# SERDES_10G0 register map
Vendor: Texas Instruments
Registers are 32-bit, access per field, reset 0x0 unless marked. A register's access mark holds for its fields unless they carry their own. Offsets are as the file gives them; [hi:lo] are bit positions; {n}, {i} and the like mark numbered series.

## SERDES_10G0 (part 4 of 8)
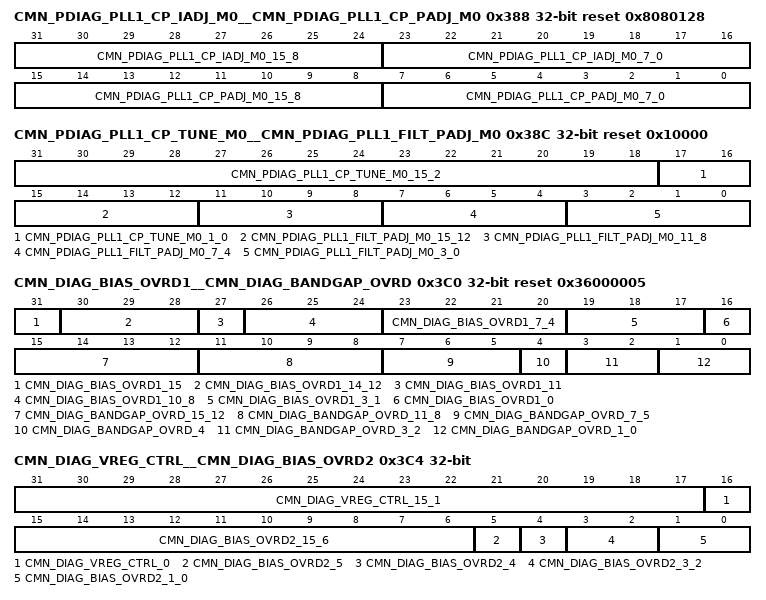
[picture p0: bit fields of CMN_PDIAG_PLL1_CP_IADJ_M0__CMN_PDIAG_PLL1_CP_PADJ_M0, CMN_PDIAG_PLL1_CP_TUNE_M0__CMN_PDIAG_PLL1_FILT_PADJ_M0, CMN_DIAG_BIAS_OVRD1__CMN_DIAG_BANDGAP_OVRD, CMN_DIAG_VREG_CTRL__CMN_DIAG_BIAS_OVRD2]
0x388 CMN_PDIAG_PLL1_CP_IADJ_M0__CMN_PDIAG_PLL1_CP_PADJ_M0 rw reset 0x8080128 — PLL 1 charge pump proportional path adjust register mode 0
  [31:24] CMN_PDIAG_PLL1_CP_IADJ_M0_15_8 — PLL charge pump integral path capacitance adjust: Adjusts the charge pump integral path capacitance, by driving the cmnda_pll1_cp_int_cap_adj signal going to the analog.
  [23:16] CMN_PDIAG_PLL1_CP_IADJ_M0_7_0 — PLL charge pump integral path current adjust: Adjusts the charge pump integral path current, by driving the cmnda_pll1_cp_int_cur_adj signal going to the analog.
  [15:8] CMN_PDIAG_PLL1_CP_PADJ_M0_15_8 — PLL charge pump proportional path capacitance adjust: Adjusts the charge pump proportional path capacitance, by driving the cmnda_pll1_cp_prop_cap_adj signal going to the analog.
  [7:0] CMN_PDIAG_PLL1_CP_PADJ_M0_7_0 — PLL charge pump proportional path current adjust: Adjusts the charge pump proportional path current, by driving the cmnda_pll1_cp_prop_cur_adj signal going to the analog.
0x38C CMN_PDIAG_PLL1_CP_TUNE_M0__CMN_PDIAG_PLL1_FILT_PADJ_M0 reset 0x10000 — PLL 1 proportional path filter adjust register mode 0
  [31:18] CMN_PDIAG_PLL1_CP_TUNE_M0_15_2 ro — Reserved
  [17:16] CMN_PDIAG_PLL1_CP_TUNE_M0_1_0 rw — PLL charge pump calibration reference voltage tune: Adjusts the charge pump calibration reference voltage, by driving the cmnda_pll1_cp_vref_tune signal going to the analog.
  [15:12] CMN_PDIAG_PLL1_FILT_PADJ_M0_15_12 ro — Reserved
  [11:8] CMN_PDIAG_PLL1_FILT_PADJ_M0_11_8 rw — PLL proportional path filter capacitance adjust: Adjusts the proportional path filter capacitance, by driving the cmnda_pll1_filt_c_adj signal going to the analog.
  [7:4] CMN_PDIAG_PLL1_FILT_PADJ_M0_7_4 ro — Reserved
  [3:0] CMN_PDIAG_PLL1_FILT_PADJ_M0_3_0 rw — PLL proportional path filter resistance adjust: Adjusts the proportional path filter resistance, by driving the cmnda_pll1_filt_r_adj signal going to the analog.
0x3C0 CMN_DIAG_BIAS_OVRD1__CMN_DIAG_BANDGAP_OVRD reset 0x36000005 — Bandgap override register
  [31] CMN_DIAG_BIAS_OVRD1_15 ro — Reserved
  [30:28] CMN_DIAG_BIAS_OVRD1_14_12 rw — Receiver resistor calibration current adjust: This field is used to adjust the receiver resistor calibration bias current.
  [27] CMN_DIAG_BIAS_OVRD1_11 ro — Reserved
  [26:24] CMN_DIAG_BIAS_OVRD1_10_8 rw — Transmitter resistor calibration current adjust: This field is used to adjust the transmitter resistor calibration bias current.
  [23:20] CMN_DIAG_BIAS_OVRD1_7_4 rw — Reserved - spare
  [19:17] CMN_DIAG_BIAS_OVRD1_3_1 ro — Reserved
  [16] CMN_DIAG_BIAS_OVRD1_0 rw — Reserved - spare
  [15:12] CMN_DIAG_BANDGAP_OVRD_15_12 ro — Reserved
  [11:8] CMN_DIAG_BANDGAP_OVRD_11_8 ro — Bandgap startup circuit startup count : Identifies the status of the bandgap startup counter.
  [7:5] CMN_DIAG_BANDGAP_OVRD_7_5 ro — Reserved
  [4] CMN_DIAG_BANDGAP_OVRD_4 rw — Bandgap startup circuit select : Selects the startup circuit to be used for the bias / bandgap circuits, by driving the cmnda_bias_bg_start_sel signal going to the analog.
  [3:2] CMN_DIAG_BANDGAP_OVRD_3_2 rw — Bandgap startup circuit sense voltage adjust : This field is used to adjust the bandgap startup circuit sense voltage, by driving the cmnda_bias_bg_start_adj signal to the analog.
  [1:0] CMN_DIAG_BANDGAP_OVRD_1_0 rw — Bandgap voltage adjust : This field is used to adjust the bandgap voltage, by driving the cmnda_bias_bg_adj signal to the analog.
0x3C4 CMN_DIAG_VREG_CTRL__CMN_DIAG_BIAS_OVRD2 — Bias override register 2
  [31:17] CMN_DIAG_VREG_CTRL_15_1 ro — Reserved
  [16] CMN_DIAG_VREG_CTRL_0 rw — Voltage regulator reference voltage select: Selects the reference voltage used for the voltage regulator in common, by driving the cmnda_vreg_ref_sel signal to the analog.
  [15:6] CMN_DIAG_BIAS_OVRD2_15_6 ro — Reserved
  [5] CMN_DIAG_BIAS_OVRD2_5 rw — Bias filter bypass enable override enable: When active (1'b1), the bias filter bypass enable override bit in this register, can be used to directly control the bias filter bypass enable function.
  [4] CMN_DIAG_BIAS_OVRD2_4 rw — Bias filter bypass enable override: When enabled by the bias filter bypass enable override enable bit in this register, this bit will directly control the bias filter bypass enable function.
  [3:2] CMN_DIAG_BIAS_OVRD2_3_2 ro — Reserved
  [1:0] CMN_DIAG_BIAS_OVRD2_1_0 rw — Regulator bandgap reference voltage adjust: This field is used to adjust the regulator bandgap reference voltage, by driving the cmnda_bias_vreg_adj signal to the analog.
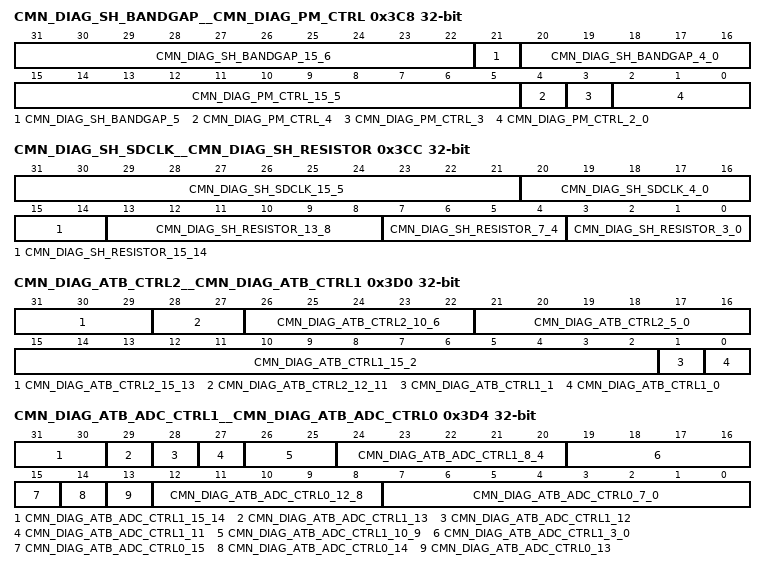
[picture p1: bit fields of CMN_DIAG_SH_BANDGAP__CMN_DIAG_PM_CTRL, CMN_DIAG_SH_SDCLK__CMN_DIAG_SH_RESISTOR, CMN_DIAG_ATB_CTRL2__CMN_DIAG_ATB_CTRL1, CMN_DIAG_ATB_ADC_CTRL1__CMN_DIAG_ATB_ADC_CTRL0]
0x3C8 CMN_DIAG_SH_BANDGAP__CMN_DIAG_PM_CTRL — Common process monitor control register
  [31:22] CMN_DIAG_SH_BANDGAP_15_6 ro — Reserved
  [21] CMN_DIAG_SH_BANDGAP_5 ro — Bandgap up value: Bandgap calibration up signal value, as it is currently captured in the sample and hold latches.
  [20:16] CMN_DIAG_SH_BANDGAP_4_0 ro — Bandgap auto zero select value: Bandgap calibration auto zero select signal value, as it is currently captured in the sample and hold latches.
  [15:5] CMN_DIAG_PM_CTRL_15_5 ro — Reserved
  [4] CMN_DIAG_PM_CTRL_4 rw — Process monitor enable: Enables the analog process monitor, by driving the cmnda_pcm_en signal to the analog.
  [3] CMN_DIAG_PM_CTRL_3 ro — Reserved
  [2:0] CMN_DIAG_PM_CTRL_2_0 rw — Process monitor mode select: Selects the mode of the analog process monitor, by driving the cmnda_pcm_sel signal to the analog.
0x3CC CMN_DIAG_SH_SDCLK__CMN_DIAG_SH_RESISTOR ro — Sample and hold resistor calibration code register
  [31:21] CMN_DIAG_SH_SDCLK_15_5 — Reserved
  [20:16] CMN_DIAG_SH_SDCLK_4_0 — Signal detect clock code: Signal detect clock calibration code signal value, as it is currently captured in the sample and hold latches.
  [15:14] CMN_DIAG_SH_RESISTOR_15_14 — Reserved
  [13:8] CMN_DIAG_SH_RESISTOR_13_8 — TX resistor code: TX resistor calibration code signal value, as it is currently captured in the sample and hold latches.
  [7:4] CMN_DIAG_SH_RESISTOR_7_4 — Reserved
  [3:0] CMN_DIAG_SH_RESISTOR_3_0 — RX resistor code: RX resistor calibration code signal value, as it is currently captured in the sample and hold latches.
0x3D0 CMN_DIAG_ATB_CTRL2__CMN_DIAG_ATB_CTRL1 — ATB control register 1
  [31:29] CMN_DIAG_ATB_CTRL2_15_13 ro — Reserved
  [28:27] CMN_DIAG_ATB_CTRL2_12_11 rw — ATB component type select: These bits specify which component type is currently selected by the ATB, as specified below.
  [26:22] CMN_DIAG_ATB_CTRL2_10_6 rw — ATB component sub address: Specifies the sub address of the component being selected.
  [21:16] CMN_DIAG_ATB_CTRL2_5_0 rw — ATB test point address: Specifies the exact point in the selected analog component to be observed.
  [15:2] CMN_DIAG_ATB_CTRL1_15_2 ro — Reserved
  [1] CMN_DIAG_ATB_CTRL1_1 rw — Core side ATB enable: When active (1'b) and the ATB enable bit in this register is also active, the ATB signals will be driven on the core side ATB signals.
  [0] CMN_DIAG_ATB_CTRL1_0 rw — ATB enable: When active (1'b1), the ATB test function is enabled.
0x3D4 CMN_DIAG_ATB_ADC_CTRL1__CMN_DIAG_ATB_ADC_CTRL0 — ATB ADC control register 0
  [31:30] CMN_DIAG_ATB_ADC_CTRL1_15_14 ro — Reserved
  [29] CMN_DIAG_ATB_ADC_CTRL1_13 rw — ATB ADC offset correction enable : Enables internal auto generated offset correction mode, by driving the cmnda_atba2d_en_off_cor signal to the analog.
  [28] CMN_DIAG_ATB_ADC_CTRL1_12 rw — ATB ADC force cap values : Forces a positive or negative voltage on the internal cap, by driving the cmnda_atba2d_frc_val signal to the analog.
  [27] CMN_DIAG_ATB_ADC_CTRL1_11 rw — ATB ADC enable manual offset correction : When this signal is active, the value in the ATB ADC manual offset correction value field of this register is used to manually control the offset correction, by driving the cmnda_atba2d_off_byp_en signal to the analog.
  [26:25] CMN_DIAG_ATB_ADC_CTRL1_10_9 ro — Reserved
  [24:20] CMN_DIAG_ATB_ADC_CTRL1_8_4 rw — ATB ADC manual offset correction value : When the ATB ADC enable manual offset correction bit in this register is active, this field is used to manually control the offset correction, by driving the cmnda_atba2d_off_adj_byp signal to the analog.
  [19:16] CMN_DIAG_ATB_ADC_CTRL1_3_0 rw — ATB ADC mode : This field indicates the mode the analog to digital converter is in.
  [15] CMN_DIAG_ATB_ADC_CTRL0_15 rw — ATB analog ADC enable: This enables the analog ADC function, by driving the cmnda_atba2d_en signal to the analog.
  [14] CMN_DIAG_ATB_ADC_CTRL0_14 rw — Start ATB ADC process: Activating (1'b1) this bit will start the ATB ADC process.
  [13] CMN_DIAG_ATB_ADC_CTRL0_13 ro — ATB ADC process done: This bit will be set to 1'b1 when the ATB ADC process is complete, and the data in the ATB ADC code field of this register is considered valid.
  [12:8] CMN_DIAG_ATB_ADC_CTRL0_12_8 ro — Reserved
  [7:0] CMN_DIAG_ATB_ADC_CTRL0_7_0 ro — ATB ADC data code: This is the digital code representing the level of the analog ATB signal that was digitized by the analog ADC.
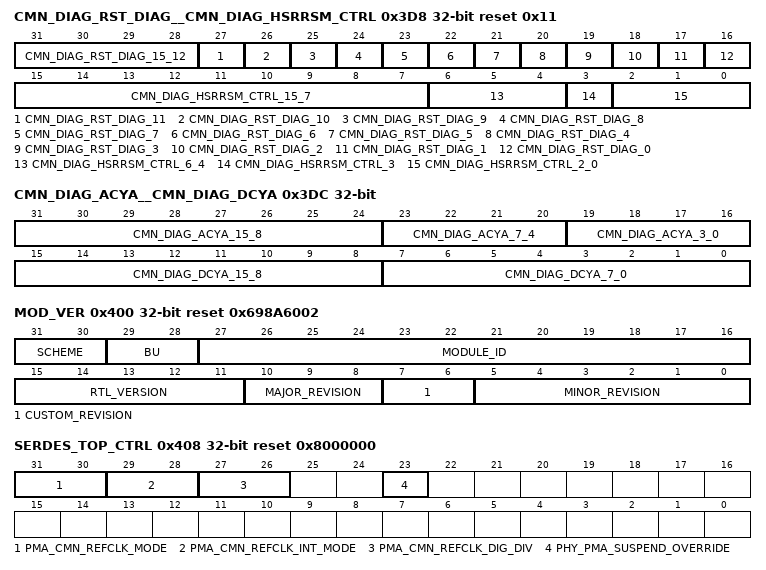
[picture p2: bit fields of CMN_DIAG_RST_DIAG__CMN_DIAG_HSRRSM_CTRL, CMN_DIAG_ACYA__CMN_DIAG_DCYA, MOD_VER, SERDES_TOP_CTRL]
0x3D8 CMN_DIAG_RST_DIAG__CMN_DIAG_HSRRSM_CTRL reset 0x11 — Common high speed reset release state machine control register
  [31:28] CMN_DIAG_RST_DIAG_15_12 ro — Reserved
  [27] CMN_DIAG_RST_DIAG_11 ro — Current state of the cmn_sd_clk_cal_fb_clk_reset_n reset.
  [26] CMN_DIAG_RST_DIAG_10 ro — Current state of the cmn_sd_clk_cal_ref_clk_reset_n reset.
  [25] CMN_DIAG_RST_DIAG_9 ro — Current state of the cmn_pll1_dsm_reset_n reset.
  [24] CMN_DIAG_RST_DIAG_8 ro — Current state of the cmn_pll0_dsm_reset_n reset.
  [23] CMN_DIAG_RST_DIAG_7 ro — Current state of the cmn_pll1_vco_cal_fbdiv_clk_reset_n reset.
  [22] CMN_DIAG_RST_DIAG_6 ro — Current state of the cmn_pll1_lock_det_fbdiv_clk_reset_n reset.
  [21] CMN_DIAG_RST_DIAG_5 ro — Current state of the cmn_pll1_vco_cal_ref_clk_reset_n reset.
  [20] CMN_DIAG_RST_DIAG_4 ro — Current state of the cmn_pll1_lock_det_ref_clk_reset_n reset.
  [19] CMN_DIAG_RST_DIAG_3 ro — Current state of the cmn_pll0_vco_cal_fbdiv_clk_reset_n reset.
  [18] CMN_DIAG_RST_DIAG_2 ro — Current state of the cmn_pll0_lock_det_fbdiv_clk_reset_n reset.
  [17] CMN_DIAG_RST_DIAG_1 ro — Current state of the cmn_pll0_vco_cal_ref_clk_reset_n reset.
  [16] CMN_DIAG_RST_DIAG_0 ro — Current state of the cmn_pll0_lock_det_ref_clk_reset_n reset.
  [15:7] CMN_DIAG_HSRRSM_CTRL_15_7 ro — Reserved
  [6:4] CMN_DIAG_HSRRSM_CTRL_6_4 rw — Transceiver reset delay : Species the number of PSM clock cycles the transceiver common high speed reset state machine stays in the delay state.
  [3] CMN_DIAG_HSRRSM_CTRL_3 ro — Reserved
  [2:0] CMN_DIAG_HSRRSM_CTRL_2_0 rw — Transmitter reset delay : Species the number of PSM clock cycles the transmitter common high speed reset state machine stays in the delay state.
0x3DC CMN_DIAG_ACYA__CMN_DIAG_DCYA — Common digital functions cover your alternatives register
  [31:24] CMN_DIAG_ACYA_15_8 ro — Reserved
  [23:20] CMN_DIAG_ACYA_7_4 rw — Reserved - spare
  [19:16] CMN_DIAG_ACYA_3_0 rw — PLL charge pump proportional gain adjust: Adjusts the charge pump gain for the PLLs to help manage bandwidth.
  [15:8] CMN_DIAG_DCYA_15_8 ro — Reserved
  [7:0] CMN_DIAG_DCYA_7_0 rw — Reserved - spare
0x400 MOD_VER ro reset 0x698A6002 — The Module and Version Register identifies the module identifier and revision of the WIZmodule.
  [31:30] SCHEME — Module Scheme
  [29:28] BU — Module BU
  [27:16] MODULE_ID
  [15:11] RTL_VERSION
  [10:8] MAJOR_REVISION
  [7:6] CUSTOM_REVISION
  [5:0] MINOR_REVISION
0x404 SERDES_CTRL rw — Sets the SERDES control state.
  [31] POR_EN — The POR_EN allows the system to place the SERDES in a reset state, Access to the SERDES registers are ignored.
0x408 SERDES_TOP_CTRL rw reset 0x8000000 — The SERDES Top Level Control
  [31:30] PMA_CMN_REFCLK_MODE — The PMA common differential reference clock mode - Sets the mode of operation for differential reference clock input.
  [29:28] PMA_CMN_REFCLK_INT_MODE — The PMA common internal reference clock mode - Sets the mode of operation for internal reference clock input.
  [27:26] PMA_CMN_REFCLK_DIG_DIV — The PMA common reference clock digital divide ratio select - Must be set before the de-assertion of apb_preset_n/phy_reset_n.
  [23] PHY_PMA_SUSPEND_OVERRIDE — The PHY PMA common suspend override enable:
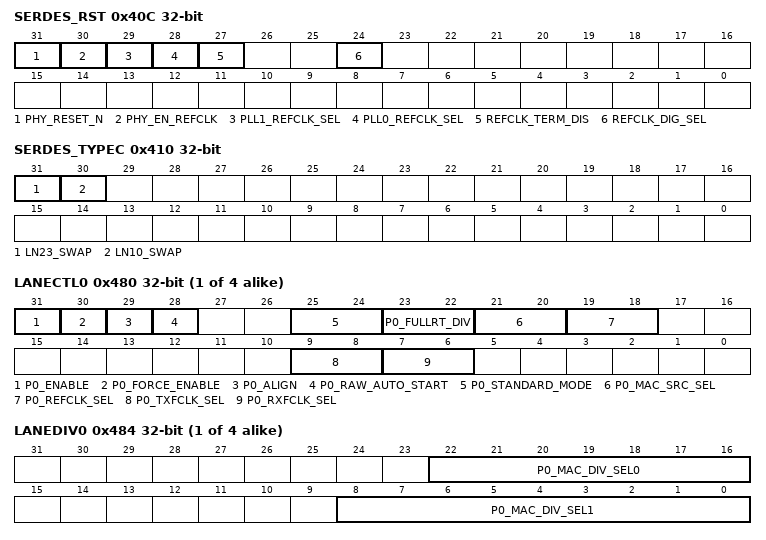
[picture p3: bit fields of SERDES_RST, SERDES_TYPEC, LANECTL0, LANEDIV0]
0x40C SERDES_RST rw — The SERDES Reset Register controls the Phy reset and REFCLK selection for the SERDES.
  [31] PHY_RESET_N — The PHY reset : Asserting this signal low will reset all PHY logic for the entire PHY with the exception of the APB registers and TAP controller.
  [30] PHY_EN_REFCLK — The PHY reference clock enable: When cmn_refclk_&lt;p/m&gt; is configured as a reference clock output,
  [29] PLL1_REFCLK_SEL — The PMA common PLL1 reference clock source select -
  [28] PLL0_REFCLK_SEL — The PMA common PLL0 reference clock source select -
  [27] REFCLK_TERM_DIS — The PMA common differential reference clock termination disable - enables/disables termination for difference reference clock input (cmn_refclk_&lt;p/m&gt;).
  [24] REFCLK_DIG_SEL — The PMA common reference clock select - Selects the reference clock source for the digital logic between cmn_refclk_&lt;p/m&gt; and pma_cmn_refclk_int.
0x410 SERDES_TYPEC rw — The SERDES Type C control register allows the external lanes selection to be swapped.
  [31] LN23_SWAP — The~iln23_swap will swap the lanes 2 and 3.
  [30] LN10_SWAP — The ~iln10_swap will swap the lanes 0 and 1.
{0x480+0x40*i} LANECTL{i} rw (i=0..3) — The Lane Control Register sets the lane specific modes of operation.
  [31] P{i}_ENABLE — The p{i}_enable is AND'd with the IPx_LNy_reset_n to enable the lane.
  [30] P{i}_FORCE_ENABLE — The p{i}_force_enable is OR'd with the IPx_LNy_reset_n to force enable the lane.
  [29] P{i}_ALIGN — The p{i}_align will auto align the RAW interface to 8B10B comma characters.
  [28] P{i}_RAW_AUTO_START — The p{i}_raw_auto_start will auto sequence the RAW interface according to the configuration settings
  [25:24] P{i}_STANDARD_MODE — Standard Mode
  [23:22] P{i}_FULLRT_DIV — Full Rate divider for 2x MAC speed mode.
  [21:20] P{i}_MAC_SRC_SEL — MAC clock source select : Selects which PMA clock to use as clock souse for pcs_mac_clk*_ln_*.
  [19:18] P{i}_REFCLK_SEL — Refclk Select determines which clocks will be used for the IP refclk signal.
  [9:8] P{i}_TXFCLK_SEL — Fclk Select determines which clocks will be used for the IP txfclk signal.
  [7:6] P{i}_RXFCLK_SEL — Fclk Select determines which clocks will be used for the IP rxfclk signal.
{0x484+0x40*i} LANEDIV{i} rw (i=0..3) — The Lane Divider Register sets the lane specific dividers of
  [22:16] P{i}_MAC_DIV_SEL0 — The reg_p{i}_mac_div_sel0 controls the divider for lane {i} MAC clock divider ratio select : Selects the divider ratio for pcs_mac_clk_divx0_ln_*.
  [8:0] P{i}_MAC_DIV_SEL1 — The reg_p{i}_mac_div_sel1 controls the divider for lane {i} MAC clock divider ratio select : Selects the divider ratio for pcs_mac_clk_divx1_ln_*.
{0x488+0x40*i} LANALIGN{i} ro (i=0..3) — The Lane Align reports the 8B10B alignment delay from the Comma aligner when 8B10B protocol is used in RAW mode.
  [5:0] P{i}_ALIGN_RX_DELAY — The reg_p{i}_align_rx_delay indicates the number of bits that are added to align the data to an 8B10B alignment.
{0x48C+0x40*i} LANESTS{i} ro (i=0..3) — The lane Status reports the lane state information for debug purposes.
  [1] P{i}_MASTER — The reg_p{i}_master indicates the lane is a base lane for a multi lane link.
0x5F8 DTB_MUX_SEL rw — The digital test bus mux select determines the value on the test bus.
  [4:0] DTB_MUX_SEL
0x5FC DIAG_TEST rw — The Diagnostic Test Register allows the system to validate the read and write of all data bits.
  [31:0] DIAG_REG — Diagnostic register.
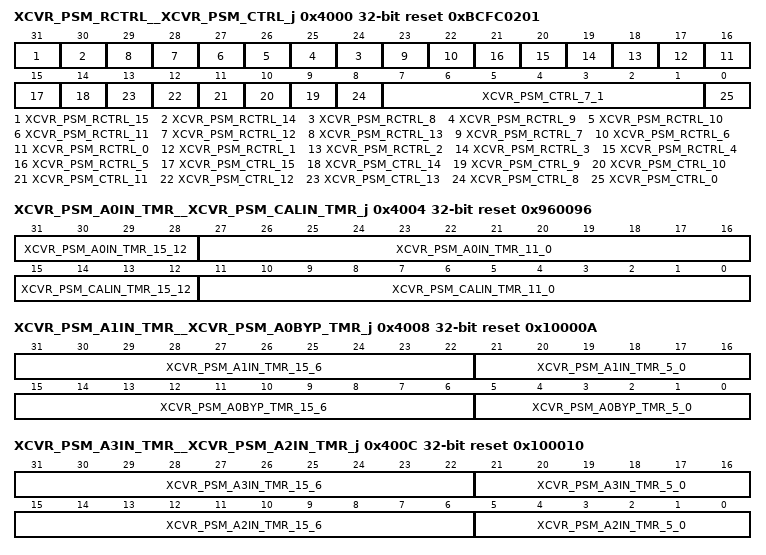
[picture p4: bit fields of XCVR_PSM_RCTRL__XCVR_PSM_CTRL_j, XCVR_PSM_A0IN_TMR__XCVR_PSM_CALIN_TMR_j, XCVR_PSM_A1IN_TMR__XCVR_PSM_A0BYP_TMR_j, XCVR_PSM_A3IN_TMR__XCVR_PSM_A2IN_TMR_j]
0x4000 XCVR_PSM_RCTRL__XCVR_PSM_CTRL_j reset 0xBCFC0201 — Power state machine control register Offset = 4000h + (j * 400h); where j = 0h to 3h
  [31] XCVR_PSM_RCTRL_15 rw — RX reset active ready : Controls the state the receiver reset is changed to when in the ready power state.
  [30] XCVR_PSM_RCTRL_14 rw — RX reset active calibration : Controls the state the receiver reset is changed to when in the calibration power state.
  [n+16] XCVR_PSM_RCTRL_{n} rw (n=8..13) — RX reset active A{n-8} : Controls the state the receiver reset is changed to when in the A{n-8} entry power state.
  [23] XCVR_PSM_RCTRL_7 rw — TX reset active ready : Controls the state the transmitter reset is changed to when in the ready power state.
  [22] XCVR_PSM_RCTRL_6 rw — TX reset active calibration : Controls the state the transmitter reset is changed to when in the calibration power state.
  [n+16] XCVR_PSM_RCTRL_{n} rw (n=0..5) — TX reset active A{n} : Controls the state the transmitter reset is changed to when in the A{n} entry power state.
  [15] XCVR_PSM_CTRL_15 ro — Reserved
  [14] XCVR_PSM_CTRL_14 rw — Bypass A0 in delay from PSM ready : When this bit is active (1'b1), the A0 input delay is bypassed when transitioning from the PSM ready state to the A0 power state.
  [n] XCVR_PSM_CTRL_{n} rw (n=9..13) — Bypass A0 in delay from A{n-8} : When this bit is active (1'b1), the A0 input delay is bypassed when transitioning from the A{n-8} to the A0 power state.
  [8] XCVR_PSM_CTRL_8 ro — Reserved
  [7:1] XCVR_PSM_CTRL_7_1 ro — Reserved
  [0] XCVR_PSM_CTRL_0 rw — Reserved - spare (must remain set to 1'b1).
0x4004 XCVR_PSM_A0IN_TMR__XCVR_PSM_CALIN_TMR_j reset 0x960096 — PSM calibration in delay timer register Offset = 4004h + (j * 400h); where j = 0h to 3h
  [31:28] XCVR_PSM_A0IN_TMR_15_12 ro — Reserved
  [27:16] XCVR_PSM_A0IN_TMR_11_0 rw — A0 in delay state timer value : Value used for the timer when the power state machine is in the A0 in delay state, unless the timer is bypassed under the control of the bypass A0 bits in the Power state machine control register.
  [15:12] XCVR_PSM_CALIN_TMR_15_12 ro — Reserved
  [11:0] XCVR_PSM_CALIN_TMR_11_0 rw — PSM calibration in delay state timer value : Value used for the timer when the power state machine is in the PSM calibration in delay state.
0x4008 XCVR_PSM_A1IN_TMR__XCVR_PSM_A0BYP_TMR_j reset 0x10000A — A0 in bypass timer register Offset = 4008h + (j * 400h); where j = 0h to 3h
  [31:22] XCVR_PSM_A1IN_TMR_15_6 ro — Reserved
  [21:16] XCVR_PSM_A1IN_TMR_5_0 rw — A1 in delay state timer value : Value used for the timer when the power state machine is in the A1 in delay state.
  [15:6] XCVR_PSM_A0BYP_TMR_15_6 ro — Reserved
  [5:0] XCVR_PSM_A0BYP_TMR_5_0 rw — A0 in delay state bypass timer value : Value used for the timer when the power state machine is in the A0 in delay state and the timer is bypassed under the control of the bypass A0 bits in the Power state machine control register.
0x400C XCVR_PSM_A3IN_TMR__XCVR_PSM_A2IN_TMR_j reset 0x100010 — A2 in delay timer register Offset = 400Ch + (j * 400h); where j = 0h to 3h
  [31:22] XCVR_PSM_A3IN_TMR_15_6 ro — Reserved
  [21:16] XCVR_PSM_A3IN_TMR_5_0 rw — A3 in delay state timer value : Value used for the timer when the power state machine is in the A3 in delay state.
  [15:6] XCVR_PSM_A2IN_TMR_15_6 ro — Reserved
  [5:0] XCVR_PSM_A2IN_TMR_5_0 rw — A2 in delay state timer value : Value used for the timer when the power state machine is in the A2 in delay state.
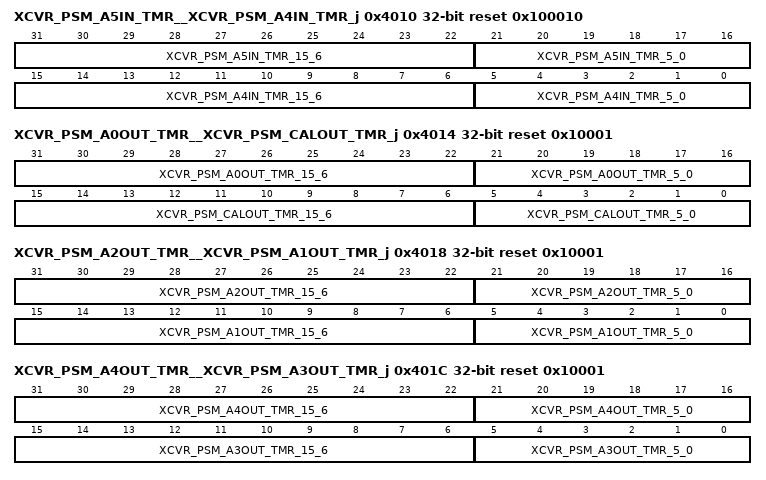
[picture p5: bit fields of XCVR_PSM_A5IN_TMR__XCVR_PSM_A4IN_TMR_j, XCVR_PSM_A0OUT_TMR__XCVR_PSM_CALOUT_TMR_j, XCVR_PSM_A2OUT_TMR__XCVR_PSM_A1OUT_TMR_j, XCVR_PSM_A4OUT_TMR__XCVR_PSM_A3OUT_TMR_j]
0x4010 XCVR_PSM_A5IN_TMR__XCVR_PSM_A4IN_TMR_j reset 0x100010 — A4 in delay timer register Offset = 4010h + (j * 400h); where j = 0h to 3h
  [31:22] XCVR_PSM_A5IN_TMR_15_6 ro — Reserved
  [21:16] XCVR_PSM_A5IN_TMR_5_0 rw — A5 in delay state timer value : Value used for the timer when the power state machine is in the A5 in delay state.
  [15:6] XCVR_PSM_A4IN_TMR_15_6 ro — Reserved
  [5:0] XCVR_PSM_A4IN_TMR_5_0 rw — A4 in delay state timer value : Value used for the timer when the power state machine is in the A4 in delay state.
0x4014 XCVR_PSM_A0OUT_TMR__XCVR_PSM_CALOUT_TMR_j reset 0x10001 — PSM calibration out delay timer register Offset = 4014h + (j * 400h); where j = 0h to 3h
  [31:22] XCVR_PSM_A0OUT_TMR_15_6 ro — Reserved
  [21:16] XCVR_PSM_A0OUT_TMR_5_0 rw — A0 out delay state timer value : Value used for the timer when the power state machine is in the A0 out delay state.
  [15:6] XCVR_PSM_CALOUT_TMR_15_6 ro — Reserved
  [5:0] XCVR_PSM_CALOUT_TMR_5_0 rw — PSM calibration out delay state timer value : Value used for the timer when the power state machine is in the PSM calibration out delay state.
0x4018 XCVR_PSM_A2OUT_TMR__XCVR_PSM_A1OUT_TMR_j reset 0x10001 — A1 out delay timer register Offset = 4018h + (j * 400h); where j = 0h to 3h
  [31:22] XCVR_PSM_A2OUT_TMR_15_6 ro — Reserved
  [21:16] XCVR_PSM_A2OUT_TMR_5_0 rw — A2 out delay state timer value : Value used for the timer when the power state machine is in the A2 out delay state.
  [15:6] XCVR_PSM_A1OUT_TMR_15_6 ro — Reserved
  [5:0] XCVR_PSM_A1OUT_TMR_5_0 rw — A1 out delay state timer value : Value used for the timer when the power state machine is in the A1 out delay state.
0x401C XCVR_PSM_A4OUT_TMR__XCVR_PSM_A3OUT_TMR_j reset 0x10001 — A3 out delay timer register Offset = 401Ch + (j * 400h); where j = 0h to 3h
  [31:22] XCVR_PSM_A4OUT_TMR_15_6 ro — Reserved
  [21:16] XCVR_PSM_A4OUT_TMR_5_0 rw — A4 out delay state timer value : Value used for the timer when the power state machine is in the A4 out delay state.
  [15:6] XCVR_PSM_A3OUT_TMR_15_6 ro — Reserved
  [5:0] XCVR_PSM_A3OUT_TMR_5_0 rw — A3 out delay state timer value : Value used for the timer when the power state machine is in the A3 out delay state.
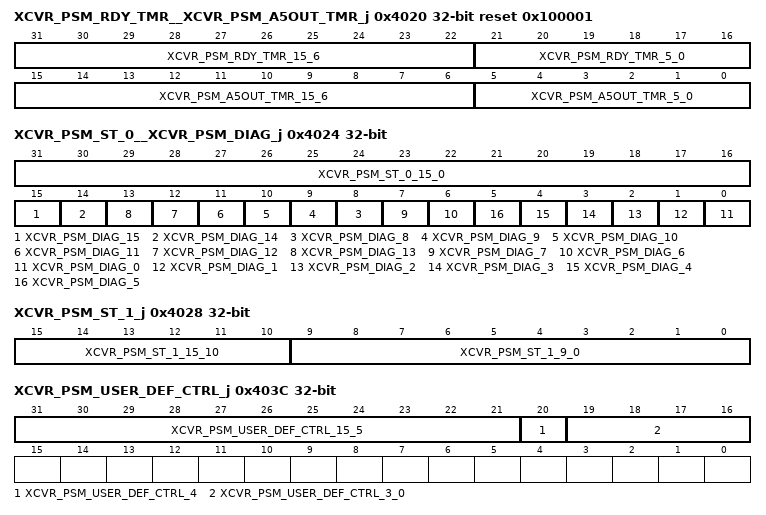
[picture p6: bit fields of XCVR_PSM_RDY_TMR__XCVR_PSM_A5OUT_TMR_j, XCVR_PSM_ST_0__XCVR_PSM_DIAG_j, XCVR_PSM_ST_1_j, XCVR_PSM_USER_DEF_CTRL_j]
0x4020 XCVR_PSM_RDY_TMR__XCVR_PSM_A5OUT_TMR_j reset 0x100001 — A5 out delay timer register Offset = 4020h + (j * 400h); where j = 0h to 3h
  [31:22] XCVR_PSM_RDY_TMR_15_6 ro — Reserved
  [21:16] XCVR_PSM_RDY_TMR_5_0 rw — Ready delay state timer value : Value used for the timer when the power state machine is in the ready state.
  [15:6] XCVR_PSM_A5OUT_TMR_15_6 ro — Reserved
  [5:0] XCVR_PSM_A5OUT_TMR_5_0 rw — A5 out delay state timer value : Value used for the timer when the power state machine is in the A5 out delay state.
0x4024 XCVR_PSM_ST_0__XCVR_PSM_DIAG_j — Power state machine diagnostic register Offset = 4024h + (j * 400h); where j = 0h to 3h
  [31:16] XCVR_PSM_ST_0_15_0 ro — PSM current state [15:0] : Indicates bits 15:0 of the current state of the power state machine.
  [15] XCVR_PSM_DIAG_15 ro — Reserved
  [14] XCVR_PSM_DIAG_14 rw — Force calibration exit acknowledge : Setting this bit to 1'b1 forces the psm_cal_exit_ack pin of the power state machine active.
  [n] XCVR_PSM_DIAG_{n} rw (n=8..13) — Force A{n-8} exit acknowledge : Setting this bit to 1'b1 forces the psm_a{n-8}_exit_ack pin of the power state machine active.
  [7] XCVR_PSM_DIAG_7 ro — Reserved
  [6] XCVR_PSM_DIAG_6 rw — Force calibration entry acknowledge : Setting this bit to 1'b1 forces the psm_cal_entry_ack pin of the power state machine active.
  [n] XCVR_PSM_DIAG_{n} rw (n=0..5) — Force A{n} entry acknowledge : Setting this bit to 1'b1 forces the psm_a{n}_entry_ack pin of the power state machine active.
0x4028 XCVR_PSM_ST_1_j ro — PSM current state register 1 Offset = 4028h + (j * 400h); where j = 0h to 3h
  [15:10] XCVR_PSM_ST_1_15_10 — Reserved
  [9:0] XCVR_PSM_ST_1_9_0 — PSM current state [25:16] : Indicates bits 25:16 of the current state of the power state machine.
0x403C XCVR_PSM_USER_DEF_CTRL_j rw — Power state machine user defined control register Offset = 403Ch + (j * 400h); where j = 0h to 3h
  [31:21] XCVR_PSM_USER_DEF_CTRL_15_5 — Reserved - spare
  [20] XCVR_PSM_USER_DEF_CTRL_4 — Force PSM gated clock on: Setting this bit to 1'b1 will force the PSM gated clock on, independent of the internal PSM state machine clock gate controls.
  [19:16] XCVR_PSM_USER_DEF_CTRL_3_0 — Reserved - spare
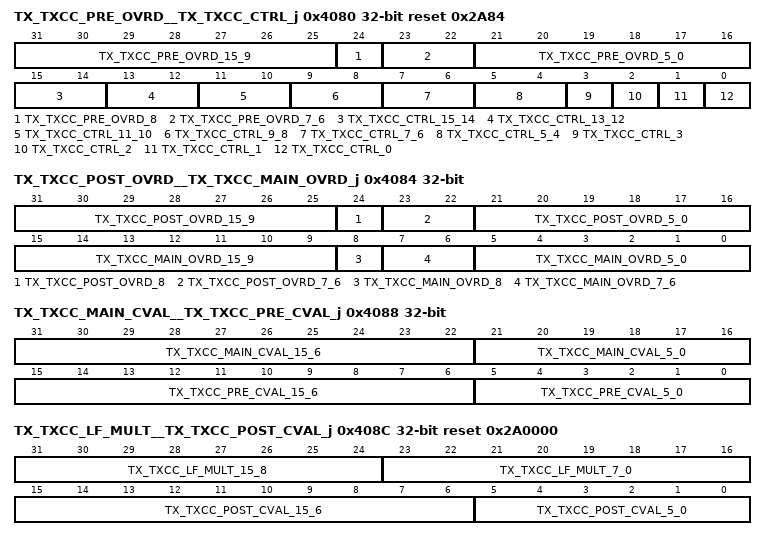
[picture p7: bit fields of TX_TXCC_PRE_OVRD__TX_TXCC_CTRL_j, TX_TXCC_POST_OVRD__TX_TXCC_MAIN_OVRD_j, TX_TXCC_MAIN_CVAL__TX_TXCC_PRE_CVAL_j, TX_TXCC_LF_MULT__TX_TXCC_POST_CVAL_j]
0x4080 TX_TXCC_PRE_OVRD__TX_TXCC_CTRL_j reset 0x2A84 — TX coefficient controller control register Offset = 4080h + (j * 400h); where j = 0h to 3h
  [31:25] TX_TXCC_PRE_OVRD_15_9 ro — Reserved
  [24] TX_TXCC_PRE_OVRD_8 rw — Pre-cursor override enable: When enabled, the pre-cursor field in this register is used to override the pre-cursor value.
  [23:22] TX_TXCC_PRE_OVRD_7_6 ro — Reserved
  [21:16] TX_TXCC_PRE_OVRD_5_0 rw — Pre-cursor override value: When enabled by the pre-cursor override enable bit in this register, the value in this field is used to override the pre-cursor value.
  [15:14] TX_TXCC_CTRL_15_14 ro — Reserved
  [13:12] TX_TXCC_CTRL_13_12 rw — Margin multiplier rounding control: This field controls the rounding function on the margin multiplier.
  [11:10] TX_TXCC_CTRL_11_10 rw — LF value multiplier rounding control: This field controls the rounding function on the LF value multiplier.
  [9:8] TX_TXCC_CTRL_9_8 rw — Calculated post-emphasis multiplier rounding control: This field controls the rounding function on the calculated post-emphasis multiplier.
  [7:6] TX_TXCC_CTRL_7_6 rw — Calculated pre-emphasis multiplier rounding control: This field controls the rounding function on the pre-emphasis multiplier.
  [5:4] TX_TXCC_CTRL_5_4 rw — Coefficient calculator multiplier rounding control: This field controls the rounding function on the coefficient calculator multiplier.
  [3] TX_TXCC_CTRL_3 rw — De-emphasis control standard mode 3 value: This bit controls the de-emphasis mode when the xcvr_standard_mode is set to 2'b11.
  [2] TX_TXCC_CTRL_2 rw — De-emphasis control standard mode 2 value: This bit controls the de-emphasis mode when the xcvr_standard_mode is set to 2'b10.
  [1] TX_TXCC_CTRL_1 rw — De-emphasis control standard mode 1 value: This bit controls the de-emphasis mode when the xcvr_standard_mode is set to 2'b01.
  [0] TX_TXCC_CTRL_0 rw — De-emphasis control standard mode 0 value: This bit controls the de-emphasis mode when the xcvr_standard_mode is set to 2'b00.
0x4084 TX_TXCC_POST_OVRD__TX_TXCC_MAIN_OVRD_j — TX main-cursor override register Offset = 4084h + (j * 400h); where j = 0h to 3h
  [31:25] TX_TXCC_POST_OVRD_15_9 ro — Reserved
  [24] TX_TXCC_POST_OVRD_8 rw — Post-cursor override enable: When enabled, the post-cursor field in this register is used to override the post-cursor value.
  [23:22] TX_TXCC_POST_OVRD_7_6 ro — Reserved
  [21:16] TX_TXCC_POST_OVRD_5_0 rw — Post-cursor override value: When enabled by the post-cursor override enable bit in this register, the value in this field is used to override the post-cursor value.
  [15:9] TX_TXCC_MAIN_OVRD_15_9 ro — Reserved
  [8] TX_TXCC_MAIN_OVRD_8 rw — Main-cursor override enable: When enabled, the main-cursor field in this register is used to override the main-cursor value.
  [7:6] TX_TXCC_MAIN_OVRD_7_6 ro — Reserved
  [5:0] TX_TXCC_MAIN_OVRD_5_0 rw — Main-cursor override value: When enabled by the main-cursor override enable bit in this register, the value in this field is used to override the main-cursor value.
0x4088 TX_TXCC_MAIN_CVAL__TX_TXCC_PRE_CVAL_j ro — TX pre-cursor current value register Offset = 4088h + (j * 400h); where j = 0h to 3h
  [31:22] TX_TXCC_MAIN_CVAL_15_6 — Reserved
  [21:16] TX_TXCC_MAIN_CVAL_5_0 — Main-cursor value: The value in this field indicates the current value of the main-cursor (C0) coefficient.
  [15:6] TX_TXCC_PRE_CVAL_15_6 — Reserved
  [5:0] TX_TXCC_PRE_CVAL_5_0 — Pre-cursor value: The value in this field indicates the current value of the pre-cursor (C-1) coefficient.
0x408C TX_TXCC_LF_MULT__TX_TXCC_POST_CVAL_j reset 0x2A0000 — TX post-cursor current value register Offset = 408Ch + (j * 400h); where j = 0h to 3h
  [31:24] TX_TXCC_LF_MULT_15_8 ro — Reserved
  [23:16] TX_TXCC_LF_MULT_7_0 rw — LF multiplier value: The value in this field specifies the multiplier value used to generate the LF value from the FS value.
  [15:6] TX_TXCC_POST_CVAL_15_6 ro — Reserved
  [5:0] TX_TXCC_POST_CVAL_5_0 ro — Post-cursor value: The value in this field indicates the current value of the post-cursor (C+1) coefficient.
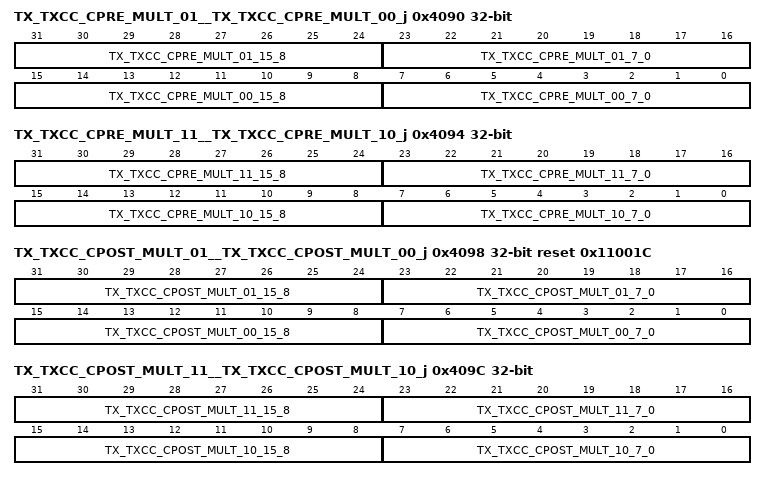
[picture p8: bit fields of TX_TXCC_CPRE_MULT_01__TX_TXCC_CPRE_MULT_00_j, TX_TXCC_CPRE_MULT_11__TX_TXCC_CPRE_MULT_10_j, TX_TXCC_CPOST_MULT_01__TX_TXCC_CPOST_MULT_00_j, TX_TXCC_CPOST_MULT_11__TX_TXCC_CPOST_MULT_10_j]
0x4090 TX_TXCC_CPRE_MULT_01__TX_TXCC_CPRE_MULT_00_j — Calculated pre emphasis multiplier value 00 register Offset = 4090h + (j * 400h); where j = 0h to 3h
  [31:24] TX_TXCC_CPRE_MULT_01_15_8 ro — Reserved
  [23:16] TX_TXCC_CPRE_MULT_01_7_0 rw — Calculated pre emphasis multiplier value 01: The value in this field specifies the multiplier value used to generate the calculated pre emphasis value from the FS value when tx_deemphasis[1:0] = 2'b01.
  [15:8] TX_TXCC_CPRE_MULT_00_15_8 ro — Reserved
  [7:0] TX_TXCC_CPRE_MULT_00_7_0 rw — Calculated pre emphasis multiplier value 00: The value in this field specifies the multiplier value used to generate the calculated pre emphasis value from the FS value when tx_deemphasis[1:0] = 2'b00.
0x4094 TX_TXCC_CPRE_MULT_11__TX_TXCC_CPRE_MULT_10_j — Calculated pre emphasis multiplier value 10 register Offset = 4094h + (j * 400h); where j = 0h to 3h
  [31:24] TX_TXCC_CPRE_MULT_11_15_8 ro — Reserved
  [23:16] TX_TXCC_CPRE_MULT_11_7_0 rw — Calculated pre emphasis multiplier value 11: The value in this field specifies the multiplier value used to generate the calculated pre emphasis value from the FS value when tx_deemphasis[1:0] = 2'b11.
  [15:8] TX_TXCC_CPRE_MULT_10_15_8 ro — Reserved
  [7:0] TX_TXCC_CPRE_MULT_10_7_0 rw — Calculated pre emphasis multiplier value 10: The value in this field specifies the multiplier value used to generate the calculated pre emphasis value from the FS value when tx_deemphasis[1:0] = 2'b10.
0x4098 TX_TXCC_CPOST_MULT_01__TX_TXCC_CPOST_MULT_00_j reset 0x11001C — Calculated post emphasis multiplier value 00 register Offset = 4098h + (j * 400h); where j = 0h to 3h
  [31:24] TX_TXCC_CPOST_MULT_01_15_8 ro — Reserved
  [23:16] TX_TXCC_CPOST_MULT_01_7_0 rw — Calculated post emphasis multiplier value 01: The value in this field specifies the multiplier value used to generate the calculated post emphasis value from the FS value when tx_deemphasis [1:0] = 2'b01.
  [15:8] TX_TXCC_CPOST_MULT_00_15_8 ro — Reserved
  [7:0] TX_TXCC_CPOST_MULT_00_7_0 rw — Calculated post emphasis multiplier value 00: The value in this field specifies the multiplier value used to generate the calculated post emphasis value from the FS value when tx_deemphasis [1:0] = 2'b00.
0x409C TX_TXCC_CPOST_MULT_11__TX_TXCC_CPOST_MULT_10_j — Calculated post emphasis multiplier value 10 register Offset = 409Ch + (j * 400h); where j = 0h to 3h
  [31:24] TX_TXCC_CPOST_MULT_11_15_8 ro — Reserved
  [23:16] TX_TXCC_CPOST_MULT_11_7_0 rw — Calculated post emphasis multiplier value 11: The value in this field specifies the multiplier value used to generate the calculated post emphasis value from the FS value when tx_deemphasis [1:0] = 2'b11.
  [15:8] TX_TXCC_CPOST_MULT_10_15_8 ro — Reserved
  [7:0] TX_TXCC_CPOST_MULT_10_7_0 rw — Calculated post emphasis multiplier value 10: The value in this field specifies the multiplier value used to generate the calculated post emphasis value from the FS value when tx_deemphasis [1:0] = 2'b10.
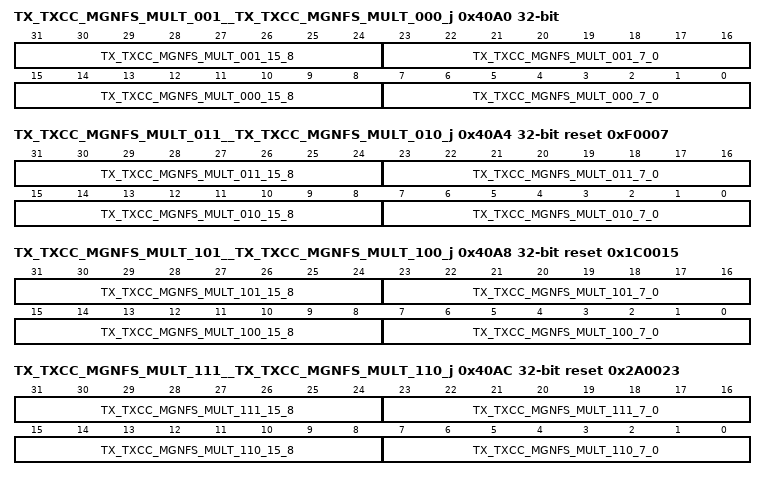
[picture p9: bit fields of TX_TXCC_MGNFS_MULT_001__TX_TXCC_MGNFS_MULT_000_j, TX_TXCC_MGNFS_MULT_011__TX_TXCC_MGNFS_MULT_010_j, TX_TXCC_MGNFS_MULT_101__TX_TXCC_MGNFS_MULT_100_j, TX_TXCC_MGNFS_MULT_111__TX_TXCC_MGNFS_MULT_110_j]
0x40A0 TX_TXCC_MGNFS_MULT_001__TX_TXCC_MGNFS_MULT_000_j — Margin full swing multiplier value 000 register Offset = 40A0h + (j * 400h); where j = 0h to 3h
  [31:24] TX_TXCC_MGNFS_MULT_001_15_8 ro — Reserved
  [23:16] TX_TXCC_MGNFS_MULT_001_7_0 rw — Margin full swing multiplier value 001: The value in this field specifies the multiplier value used to generate the margin value from the resistor calibration value when tx_vmargin = 3'b001 and tx_low_power_swing_en = 1'b0.
  [15:8] TX_TXCC_MGNFS_MULT_000_15_8 ro — Reserved
  [7:0] TX_TXCC_MGNFS_MULT_000_7_0 rw — Margin full swing multiplier value 000: The value in this field specifies the multiplier value used to generate the margin value from the resistor calibration value when tx_vmargin = 3'b000 and tx_low_power_swing_en = 1'b0.
0x40A4 TX_TXCC_MGNFS_MULT_011__TX_TXCC_MGNFS_MULT_010_j reset 0xF0007 — Margin full swing multiplier value 010 register Offset = 40A4h + (j * 400h); where j = 0h to 3h
  [31:24] TX_TXCC_MGNFS_MULT_011_15_8 ro — Reserved
  [23:16] TX_TXCC_MGNFS_MULT_011_7_0 rw — Margin full swing multiplier value 011: The value in this field specifies the multiplier value used to generate the margin value from the resistor calibration value when tx_vmargin = 3'b011 and tx_low_power_swing_en = 1'b0.
  [15:8] TX_TXCC_MGNFS_MULT_010_15_8 ro — Reserved
  [7:0] TX_TXCC_MGNFS_MULT_010_7_0 rw — Margin full swing multiplier value 010: The value in this field specifies the multiplier value used to generate the margin value from the resistor calibration value when tx_vmargin = 3'b010 and tx_low_power_swing_en = 1'b0.
0x40A8 TX_TXCC_MGNFS_MULT_101__TX_TXCC_MGNFS_MULT_100_j reset 0x1C0015 — Margin full swing multiplier value 100 register Offset = 40A8h + (j * 400h); where j = 0h to 3h
  [31:24] TX_TXCC_MGNFS_MULT_101_15_8 ro — Reserved
  [23:16] TX_TXCC_MGNFS_MULT_101_7_0 rw — Margin full swing multiplier value 101: The value in this field specifies the multiplier value used to generate the margin value from the resistor calibration value when tx_vmargin = 3'b101 and tx_low_power_swing_en = 1'b0.
  [15:8] TX_TXCC_MGNFS_MULT_100_15_8 ro — Reserved
  [7:0] TX_TXCC_MGNFS_MULT_100_7_0 rw — Margin full swing multiplier value 100: The value in this field specifies the multiplier value used to generate the margin value from the resistor calibration value when tx_vmargin = 3'b100 and tx_low_power_swing_en = 1'b0.
0x40AC TX_TXCC_MGNFS_MULT_111__TX_TXCC_MGNFS_MULT_110_j reset 0x2A0023 — Margin full swing multiplier value 110 register Offset = 40ACh + (j * 400h); where j = 0h to 3h
  [31:24] TX_TXCC_MGNFS_MULT_111_15_8 ro — Reserved
  [23:16] TX_TXCC_MGNFS_MULT_111_7_0 rw — Margin full swing multiplier value 111: The value in this field specifies the multiplier value used to generate the margin value from the resistor calibration value when tx_vmargin = 3'b111 and tx_low_power_swing_en = 1'b0.
  [15:8] TX_TXCC_MGNFS_MULT_110_15_8 ro — Reserved
  [7:0] TX_TXCC_MGNFS_MULT_110_7_0 rw — Margin full swing multiplier value 110: The value in this field specifies the multiplier value used to generate the margin value from the resistor calibration value when tx_vmargin = 3'b110 and tx_low_power_swing_en = 1'b0.
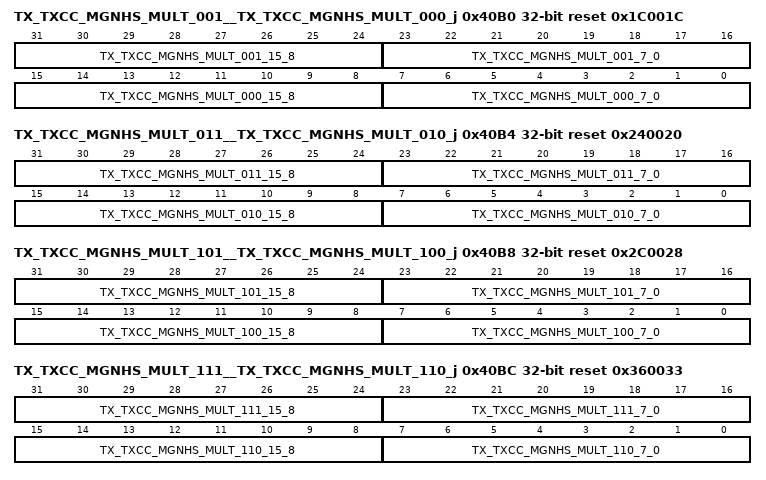
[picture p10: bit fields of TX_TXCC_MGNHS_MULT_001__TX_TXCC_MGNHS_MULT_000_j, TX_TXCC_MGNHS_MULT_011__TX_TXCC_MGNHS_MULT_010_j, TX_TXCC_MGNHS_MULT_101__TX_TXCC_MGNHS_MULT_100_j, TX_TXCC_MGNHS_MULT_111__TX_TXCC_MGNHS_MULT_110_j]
0x40B0 TX_TXCC_MGNHS_MULT_001__TX_TXCC_MGNHS_MULT_000_j reset 0x1C001C — Margin half swing multiplier value 000 register Offset = 40B0h + (j * 400h); where j = 0h to 3h
  [31:24] TX_TXCC_MGNHS_MULT_001_15_8 ro — Reserved
  [23:16] TX_TXCC_MGNHS_MULT_001_7_0 rw — Margin half swing multiplier value 001: The value in this field specifies the multiplier value used to generate the margin value from the resistor calibration value when tx_vmargin = 3'b001 and tx_low_power_swing_en = 1'b1.
  [15:8] TX_TXCC_MGNHS_MULT_000_15_8 ro — Reserved
  [7:0] TX_TXCC_MGNHS_MULT_000_7_0 rw — Margin half swing multiplier value 000: The value in this field specifies the multiplier value used to generate the margin value from the resistor calibration value when tx_vmargin = 3'b000 and tx_low_power_swing_en = 1'b1.
0x40B4 TX_TXCC_MGNHS_MULT_011__TX_TXCC_MGNHS_MULT_010_j reset 0x240020 — Margin half swing multiplier value 010 register Offset = 40B4h + (j * 400h); where j = 0h to 3h
  [31:24] TX_TXCC_MGNHS_MULT_011_15_8 ro — Reserved
  [23:16] TX_TXCC_MGNHS_MULT_011_7_0 rw — Margin half swing multiplier value 011: The value in this field specifies the multiplier value used to generate the margin value from the resistor calibration value when tx_vmargin = 3'b011 and tx_low_power_swing_en = 1'b1.
  [15:8] TX_TXCC_MGNHS_MULT_010_15_8 ro — Reserved
  [7:0] TX_TXCC_MGNHS_MULT_010_7_0 rw — Margin half swing multiplier value 010: The value in this field specifies the multiplier value used to generate the margin value from the resistor calibration value when tx_vmargin = 3'b010 and tx_low_power_swing_en = 1'b1.
0x40B8 TX_TXCC_MGNHS_MULT_101__TX_TXCC_MGNHS_MULT_100_j reset 0x2C0028 — Margin half swing multiplier value 100 register Offset = 40B8h + (j * 400h); where j = 0h to 3h
  [31:24] TX_TXCC_MGNHS_MULT_101_15_8 ro — Reserved
  [23:16] TX_TXCC_MGNHS_MULT_101_7_0 rw — Margin half swing multiplier value 101: The value in this field specifies the multiplier value used to generate the margin value from the resistor calibration value when tx_vmargin = 3'b101 and tx_low_power_swing_en = 1'b1.
  [15:8] TX_TXCC_MGNHS_MULT_100_15_8 ro — Reserved
  [7:0] TX_TXCC_MGNHS_MULT_100_7_0 rw — Margin half swing multiplier value 100: The value in this field specifies the multiplier value used to generate the margin value from the resistor calibration value when tx_vmargin = 3'b100 and tx_low_power_swing_en = 1'b1.
0x40BC TX_TXCC_MGNHS_MULT_111__TX_TXCC_MGNHS_MULT_110_j reset 0x360033 — Margin half swing multiplier value 110 register Offset = 40BCh + (j * 400h); where j = 0h to 3h
  [31:24] TX_TXCC_MGNHS_MULT_111_15_8 ro — Reserved
  [23:16] TX_TXCC_MGNHS_MULT_111_7_0 rw — Margin half swing multiplier value 111: The value in this field specifies the multiplier value used to generate the margin value from the resistor calibration value when tx_vmargin = 3'b111 and tx_low_power_swing_en = 1'b1.
  [15:8] TX_TXCC_MGNHS_MULT_110_15_8 ro — Reserved
  [7:0] TX_TXCC_MGNHS_MULT_110_7_0 rw — Margin half swing multiplier value 110: The value in this field specifies the multiplier value used to generate the margin value from the resistor calibration value when tx_vmargin = 3'b110 and tx_low_power_swing_en = 1'b1.
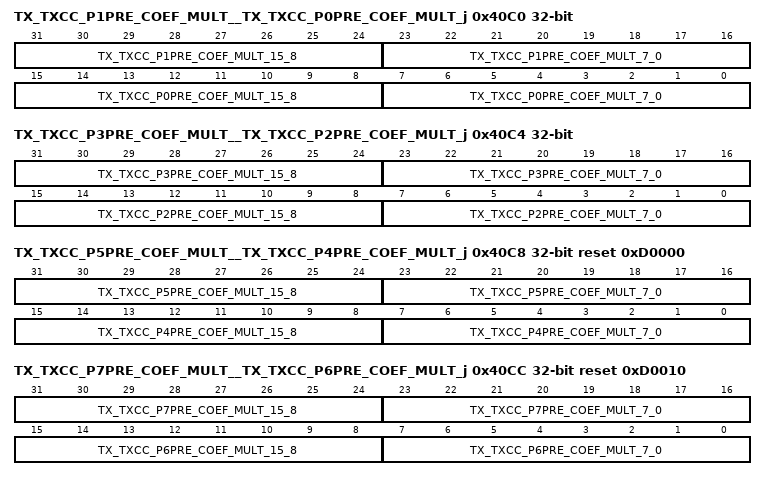
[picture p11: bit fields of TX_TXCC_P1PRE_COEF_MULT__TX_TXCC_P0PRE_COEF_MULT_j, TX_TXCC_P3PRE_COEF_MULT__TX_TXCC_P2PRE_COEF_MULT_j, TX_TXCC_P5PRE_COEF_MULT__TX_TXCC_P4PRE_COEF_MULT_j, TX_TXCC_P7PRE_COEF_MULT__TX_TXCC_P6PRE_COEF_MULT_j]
0x40C0 TX_TXCC_P1PRE_COEF_MULT__TX_TXCC_P0PRE_COEF_MULT_j — Preset 0 pre emphasis coefficient multiplier value register Offset = 40C0h + (j * 400h); where j = 0h to 3h
  [31:24] TX_TXCC_P1PRE_COEF_MULT_15_8 ro — Reserved
  [23:16] TX_TXCC_P1PRE_COEF_MULT_7_0 rw — Preset 1 pre emphasis coefficient multiplier value : The value in this field specifies the multiplier value used to generate the preset 1 pre emphasis coefficient value from the FS value.
  [15:8] TX_TXCC_P0PRE_COEF_MULT_15_8 ro — Reserved
  [7:0] TX_TXCC_P0PRE_COEF_MULT_7_0 rw — Preset 0 pre emphasis coefficient multiplier value : The value in this field specifies the multiplier value used to generate the preset 0 pre emphasis coefficient value from the FS value.
0x40C4 TX_TXCC_P3PRE_COEF_MULT__TX_TXCC_P2PRE_COEF_MULT_j — Preset 2 pre emphasis coefficient multiplier value register Offset = 40C4h + (j * 400h); where j = 0h to 3h
  [31:24] TX_TXCC_P3PRE_COEF_MULT_15_8 ro — Reserved
  [23:16] TX_TXCC_P3PRE_COEF_MULT_7_0 rw — Preset 3 pre emphasis coefficient multiplier value : The value in this field specifies the multiplier value used to generate the preset 3 pre emphasis coefficient value from the FS value.
  [15:8] TX_TXCC_P2PRE_COEF_MULT_15_8 ro — Reserved
  [7:0] TX_TXCC_P2PRE_COEF_MULT_7_0 rw — Preset 2 pre emphasis coefficient multiplier value : The value in this field specifies the multiplier value used to generate the preset 2 pre emphasis coefficient value from the FS value.
0x40C8 TX_TXCC_P5PRE_COEF_MULT__TX_TXCC_P4PRE_COEF_MULT_j reset 0xD0000 — Preset 4 pre emphasis coefficient multiplier value register Offset = 40C8h + (j * 400h); where j = 0h to 3h
  [31:24] TX_TXCC_P5PRE_COEF_MULT_15_8 ro — Reserved
  [23:16] TX_TXCC_P5PRE_COEF_MULT_7_0 rw — Preset 5 pre emphasis coefficient multiplier value : The value in this field specifies the multiplier value used to generate the preset 5 pre emphasis coefficient value from the FS value.
  [15:8] TX_TXCC_P4PRE_COEF_MULT_15_8 ro — Reserved
  [7:0] TX_TXCC_P4PRE_COEF_MULT_7_0 rw — Preset 4 pre emphasis coefficient multiplier value : The value in this field specifies the multiplier value used to generate the preset 4 pre emphasis coefficient value from the FS value.
0x40CC TX_TXCC_P7PRE_COEF_MULT__TX_TXCC_P6PRE_COEF_MULT_j reset 0xD0010 — Preset 6 pre emphasis coefficient multiplier value register Offset = 40CCh + (j * 400h); where j = 0h to 3h
  [31:24] TX_TXCC_P7PRE_COEF_MULT_15_8 ro — Reserved
  [23:16] TX_TXCC_P7PRE_COEF_MULT_7_0 rw — Preset 7 pre emphasis coefficient multiplier value : The value in this field specifies the multiplier value used to generate the preset 7 pre emphasis coefficient value from the FS value.
  [15:8] TX_TXCC_P6PRE_COEF_MULT_15_8 ro — Reserved
  [7:0] TX_TXCC_P6PRE_COEF_MULT_7_0 rw — Preset 6 pre emphasis coefficient multiplier value : The value in this field specifies the multiplier value used to generate the preset 6 pre emphasis coefficient value from the FS value.
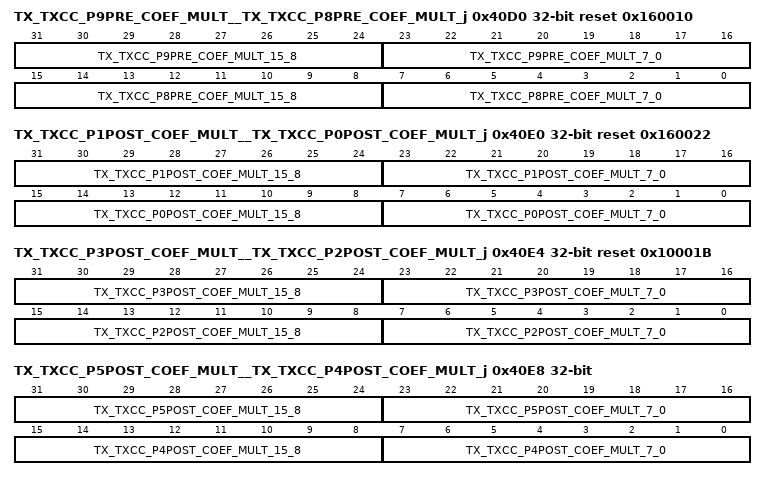
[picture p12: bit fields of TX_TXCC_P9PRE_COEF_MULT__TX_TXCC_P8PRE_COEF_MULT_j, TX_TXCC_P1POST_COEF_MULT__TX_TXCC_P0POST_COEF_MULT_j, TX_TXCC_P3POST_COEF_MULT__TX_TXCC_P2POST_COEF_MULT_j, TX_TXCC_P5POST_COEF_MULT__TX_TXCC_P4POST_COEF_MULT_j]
0x40D0 TX_TXCC_P9PRE_COEF_MULT__TX_TXCC_P8PRE_COEF_MULT_j reset 0x160010 — Preset 8 pre emphasis coefficient multiplier value register Offset = 40D0h + (j * 400h); where j = 0h to 3h
  [31:24] TX_TXCC_P9PRE_COEF_MULT_15_8 ro — Reserved
  [23:16] TX_TXCC_P9PRE_COEF_MULT_7_0 rw — Preset 9 pre emphasis coefficient multiplier value : The value in this field specifies the multiplier value used to generate the preset 9 pre emphasis coefficient value from the FS value.
  [15:8] TX_TXCC_P8PRE_COEF_MULT_15_8 ro — Reserved
  [7:0] TX_TXCC_P8PRE_COEF_MULT_7_0 rw — Preset 8 pre emphasis coefficient multiplier value : The value in this field specifies the multiplier value used to generate the preset 8 pre emphasis coefficient value from the FS value.
0x40E0 TX_TXCC_P1POST_COEF_MULT__TX_TXCC_P0POST_COEF_MULT_j reset 0x160022 — Preset 0 post emphasis coefficient multiplier value register Offset = 40E0h + (j * 400h); where j = 0h to 3h
  [31:24] TX_TXCC_P1POST_COEF_MULT_15_8 ro — Reserved
  [23:16] TX_TXCC_P1POST_COEF_MULT_7_0 rw — Preset 1 post emphasis coefficient multiplier value : The value in this field specifies the multiplier value used to generate the preset 1 post emphasis coefficient value from the FS value.
  [15:8] TX_TXCC_P0POST_COEF_MULT_15_8 ro — Reserved
  [7:0] TX_TXCC_P0POST_COEF_MULT_7_0 rw — Preset 0 post emphasis coefficient multiplier value : The value in this field specifies the multiplier value used to generate the preset 0 post emphasis coefficient value from the FS value.
0x40E4 TX_TXCC_P3POST_COEF_MULT__TX_TXCC_P2POST_COEF_MULT_j reset 0x10001B — Preset 2 post emphasis coefficient multiplier value register Offset = 40E4h + (j * 400h); where j = 0h to 3h
  [31:24] TX_TXCC_P3POST_COEF_MULT_15_8 ro — Reserved
  [23:16] TX_TXCC_P3POST_COEF_MULT_7_0 rw — Preset 3 post emphasis coefficient multiplier value : The value in this field specifies the multiplier value used to generate the preset 3 post emphasis coefficient value from the FS value.
  [15:8] TX_TXCC_P2POST_COEF_MULT_15_8 ro — Reserved
  [7:0] TX_TXCC_P2POST_COEF_MULT_7_0 rw — Preset 2 post emphasis coefficient multiplier value : The value in this field specifies the multiplier value used to generate the preset 2 post emphasis coefficient value from the FS value.
0x40E8 TX_TXCC_P5POST_COEF_MULT__TX_TXCC_P4POST_COEF_MULT_j — Preset 4 post emphasis coefficient multiplier value register Offset = 40E8h + (j * 400h); where j = 0h to 3h
  [31:24] TX_TXCC_P5POST_COEF_MULT_15_8 ro — Reserved
  [23:16] TX_TXCC_P5POST_COEF_MULT_7_0 rw — Preset 5 post emphasis coefficient multiplier value : The value in this field specifies the multiplier value used to generate the preset 5 post emphasis coefficient value from the FS value.
  [15:8] TX_TXCC_P4POST_COEF_MULT_15_8 ro — Reserved
  [7:0] TX_TXCC_P4POST_COEF_MULT_7_0 rw — Preset 4 post emphasis coefficient multiplier value : The value in this field specifies the multiplier value used to generate the preset 4 post emphasis coefficient value from the FS value.
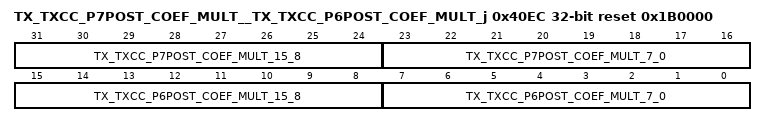
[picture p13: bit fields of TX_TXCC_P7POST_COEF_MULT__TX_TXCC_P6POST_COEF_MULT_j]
0x40EC TX_TXCC_P7POST_COEF_MULT__TX_TXCC_P6POST_COEF_MULT_j reset 0x1B0000 — Preset 6 post emphasis coefficient multiplier value register Offset = 40ECh + (j * 400h); where j = 0h to 3h
  [31:24] TX_TXCC_P7POST_COEF_MULT_15_8 ro — Reserved
  [23:16] TX_TXCC_P7POST_COEF_MULT_7_0 rw — Preset 7 post emphasis coefficient multiplier value : The value in this field specifies the multiplier value used to generate the preset 7 post emphasis coefficient value from the FS value.
  [15:8] TX_TXCC_P6POST_COEF_MULT_15_8 ro — Reserved
  [7:0] TX_TXCC_P6POST_COEF_MULT_7_0 rw — Preset 6 post emphasis coefficient multiplier value : The value in this field specifies the multiplier value used to generate the preset 6 post emphasis coefficient value from the FS value.
